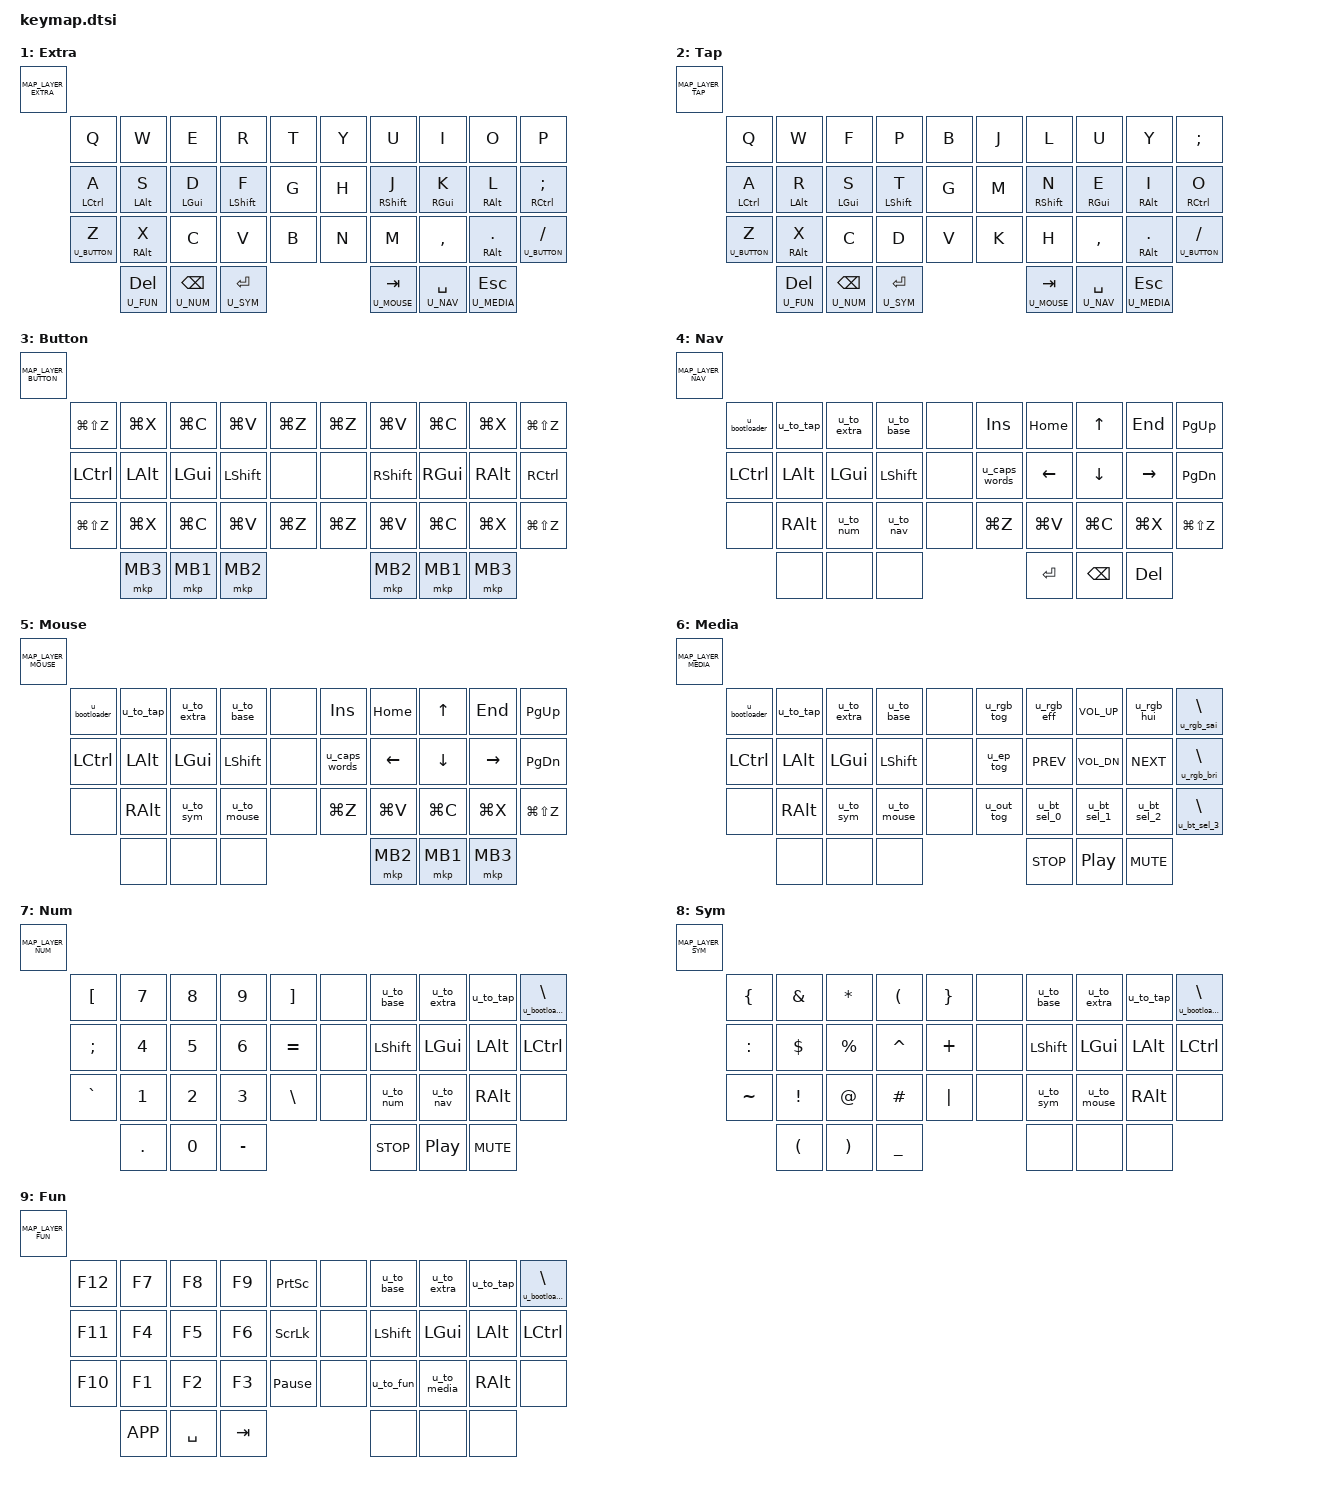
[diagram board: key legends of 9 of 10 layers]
#include <behaviors.dtsi>
#include <dt-bindings/zmk/bt.h>
#include <dt-bindings/zmk/keys.h>
#include <dt-bindings/zmk/mouse.h>
#include <dt-bindings/zmk/rgb.h>
#include <dt-bindings/zmk/ext_power.h>
#include <dt-bindings/zmk/outputs.h>

#include "default.h"

#define U_BASE   0
#define U_EXTRA  1
#define U_TAP    2
#define U_BUTTON 3
#define U_NAV    4
#define U_MOUSE  5
#define U_MEDIA  6
#define U_NUM    7
#define U_SYM    8
#define U_FUN    9

#define shift_mod_morph(NAME, BINDING, S_BINDING) \
  NAME: NAME {\
    compatible = "zmk,behavior-mod-morph";\
    bindings = <BINDING>, <S_BINDING>;\
    #binding-cells = <0>;\
    mods = <(MOD_LSFT|MOD_RSFT)>;\
  };

#define double_tap_guard(NAME, BINDING) \
  NAME: NAME {\
    compatible = "zmk,behavior-tap-dance";\
    #binding-cells = <0>;\
    tapping-term-ms = <200>;\
    bindings = <&none>, <BINDING>;\
  };

#define U_UND &kp LG(LS(Z))
#define U_CUT &kp LG(X)
#define U_CPY &kp LG(C)
#define U_PST &kp LG(V)
#define U_RDO &kp LG(Z)

#define U_BTN1 &mkp MB1
#define U_BTN2 &mkp MB2
#define U_BTN3 &mkp MB3


/ {
  behaviors {
    shift_mod_morph(sqt_under, &kp SQT, &kp UNDERSCORE)
    shift_mod_morph(minus_dqt, &kp MINUS, &kp DQT)
    shift_mod_morph(slash_lt, &kp SLASH, &kp LT)

    shift_mod_morph(u_caps_words, &caps_word, &kp CAPS)

    shift_mod_morph(u_rgb_tog, &rgb_ug RGB_TOG, &rgb_ug RGB_OFF)
    shift_mod_morph(u_rgb_eff, &rgb_ug RGB_EFF, &rgb_ug RGB_EFR)
    shift_mod_morph(u_rgb_hui, &rgb_ug RGB_HUI, &rgb_ug RGB_HUD)
    shift_mod_morph(u_rgb_sai, &rgb_ug RGB_SAI, &rgb_ug RGB_SAD)
    shift_mod_morph(u_rgb_bri, &rgb_ug RGB_BRI, &rgb_ug RGB_BRD)

    shift_mod_morph(u_ep_tog, &ext_power EP_TOG, &ext_power EP_OFF)

    shift_mod_morph(u_out_tog, &out OUT_TOG, &out OUT_USB)
    shift_mod_morph(u_bt_sel_0, &bt BT_SEL 0, &bt BT_SEL 0 &bt BT_CLR)
    shift_mod_morph(u_bt_sel_1, &bt BT_SEL 1, &bt BT_SEL 1 &bt BT_CLR)
    shift_mod_morph(u_bt_sel_2, &bt BT_SEL 2, &bt BT_SEL 2 &bt BT_CLR)
    shift_mod_morph(u_bt_sel_3, &bt BT_SEL 3, &bt BT_SEL 3 &bt BT_CLR)

    double_tap_guard(u_to_base, &to U_BASE)
    double_tap_guard(u_to_extra, &to U_EXTRA)
    double_tap_guard(u_to_tap, &to U_TAP)
    double_tap_guard(u_to_nav, &to U_NAV)
    double_tap_guard(u_to_mouse, &to U_MOUSE)
    double_tap_guard(u_to_media, &to U_MEDIA)
    double_tap_guard(u_to_num, &to U_NUM)
    double_tap_guard(u_to_sym, &to U_SYM)
    double_tap_guard(u_to_fun, &to U_FUN)
    double_tap_guard(u_bootloader, &bootloader)

    hm: hm {
      compatible = "zmk,behavior-hold-tap";
      #binding-cells = <2>;
      tapping-term-ms = <200>;
      quick-tap-ms = <0>;
      flavor = "tap-preferred";
      bindings = <&kp>, <&kp>;
    };

    u_lt: u_lt {
      compatible = "zmk,behavior-hold-tap";
      #binding-cells = <2>;
      tapping-term-ms = <200>;
      flavor = "tap-preferred";
      bindings = <&mo>, <&kp>;
    };
  };

  keymap {
    compatible = "zmk,keymap";

    Base {
      bindings = <MAP_LAYER_BASE( \
      // ╭─────────────┬─────────────┬─────────────┬─────────────┬─────────────╮   ╭─────────────┬─────────────┬─────────────┬─────────────┬─────────────╮
           &kp B,        &kp L,        &kp D,        &kp W,        &kp Z,            &sqt_under,   &kp F,        &kp O,        &kp U,        &kp J,      \
      // ├─────────────┼─────────────┼─────────────┼─────────────┼─────────────┤   ├─────────────┼─────────────┼─────────────┼─────────────┼─────────────┤
           &hm LCTRL N,  &hm LALT R,   &hm LGUI T,   &hm LSHIFT S, &kp G,            &kp Y,        &hm LSHIFT H, &hm LGUI A,   &hm LALT E,   &hm LCTRL I,\
      // ├─────────────┼─────────────┼─────────────┼─────────────┼─────────────┤   ├─────────────┼─────────────┼─────────────┼─────────────┼─────────────┤
           &u_lt U_BUTTON Q,&hm RALT X,&kp M,        &kp C,        &kp V,            &kp K,   &kp P,&kp DOT,&hm RALT &minus_dqt,&u_lt U_BUTTON &slash_lt,\
      // ╰─────────┬───┴─────────────┴─────────────┼─────────────┼─────────────┤   ├─────────────┼─────────────┼─────────────┴─────────────┴───┬─────────╯
                     &u_lt U_FUN DEL,    &u_lt U_NUM BSPC,   &u_lt U_SYM RET,        &u_lt U_MOUSE TAB,  &u_lt U_NAV SPACE,  &u_lt U_MEDIA ESC \
      //           ╰───────────────────┴───────────────────┴───────────────────╯   ╰───────────────────┴───────────────────┴───────────────────╯
      )>;
    };

    Extra {
      bindings = <MAP_LAYER_EXTRA( \
      // ╭─────────────┬─────────────┬─────────────┬─────────────┬─────────────╮   ╭─────────────┬─────────────┬─────────────┬─────────────┬─────────────╮
           &kp Q,        &kp W,        &kp E,        &kp R,        &kp T,            &kp Y,        &kp U,        &kp I,        &kp O,        &kp P,      \
      // ├─────────────┼─────────────┼─────────────┼─────────────┼─────────────┤   ├─────────────┼─────────────┼─────────────┼─────────────┼─────────────┤
           &hm LCTRL A,  &hm LALT S,   &hm LGUI D,   &hm LSHIFT F, &kp G,            &kp H,        &hm RSHIFT J, &hm RGUI K,   &hm RALT L,&hm RCTRL SEMI,\
      // ├─────────────┼─────────────┼─────────────┼─────────────┼─────────────┤   ├─────────────┼─────────────┼─────────────┼─────────────┼─────────────┤
           &u_lt U_BUTTON Z,&hm RALT X,&kp C,        &kp V,        &kp B,            &kp N,        &kp M,    &kp COMMA,&hm RALT DOT,&u_lt U_BUTTON SLASH,\
      // ╰─────────┬───┴─────────────┴─────────────┼─────────────┼─────────────┤   ├─────────────┼─────────────┼─────────────┴─────────────┴───┬─────────╯
                     &u_lt U_FUN DEL,    &u_lt U_NUM BSPC,   &u_lt U_SYM RET,        &u_lt U_MOUSE TAB,  &u_lt U_NAV SPACE,  &u_lt U_MEDIA ESC \
      //           ╰───────────────────┴───────────────────┴───────────────────╯   ╰───────────────────┴───────────────────┴───────────────────╯
      )>;
    };
    Tap {
      bindings = <MAP_LAYER_TAP( \
      // ╭─────────────┬─────────────┬─────────────┬─────────────┬─────────────╮   ╭─────────────┬─────────────┬─────────────┬─────────────┬─────────────╮
           &kp Q,        &kp W,        &kp F,        &kp P,        &kp B,            &kp J,        &kp L,        &kp U,        &kp Y,        &kp SEMI,   \
      // ├─────────────┼─────────────┼─────────────┼─────────────┼─────────────┤   ├─────────────┼─────────────┼─────────────┼─────────────┼─────────────┤
           &hm LCTRL A,  &hm LALT R,   &hm LGUI S,   &hm LSHIFT T, &kp G,            &kp M,        &hm RSHIFT N, &hm RGUI E,   &hm RALT I,   &hm RCTRL O,\
      // ├─────────────┼─────────────┼─────────────┼─────────────┼─────────────┤   ├─────────────┼─────────────┼─────────────┼─────────────┼─────────────┤
           &u_lt U_BUTTON Z,&hm RALT X,&kp C,        &kp D,        &kp V,            &kp K,        &kp H,    &kp COMMA,&hm RALT DOT,&u_lt U_BUTTON SLASH,\
      // ╰─────────┬───┴─────────────┴─────────────┼─────────────┼─────────────┤   ├─────────────┼─────────────┼─────────────┴─────────────┴───┬─────────╯
                     &u_lt U_FUN DEL,    &u_lt U_NUM BSPC,   &u_lt U_SYM RET,        &u_lt U_MOUSE TAB,  &u_lt U_NAV SPACE,  &u_lt U_MEDIA ESC \
      //           ╰───────────────────┴───────────────────┴───────────────────╯   ╰───────────────────┴───────────────────┴───────────────────╯
      )>;
    };
    Button {
      bindings = <MAP_LAYER_BUTTON( \
      // ╭─────────────┬─────────────┬─────────────┬─────────────┬─────────────╮   ╭─────────────┬─────────────┬─────────────┬─────────────┬─────────────╮
           U_UND,        U_CUT,        U_CPY,        U_PST,        U_RDO,            U_RDO,        U_PST,        U_CPY,        U_CUT,        U_UND,      \
      // ├─────────────┼─────────────┼─────────────┼─────────────┼─────────────┤   ├─────────────┼─────────────┼─────────────┼─────────────┼─────────────┤
           &kp LCTRL,    &kp LALT,     &kp LGUI,     &kp LSHIFT,   &none,            &none,        &kp RSHIFT,   &kp RGUI,     &kp RALT,     &kp RCTRL,  \
      // ├─────────────┼─────────────┼─────────────┼─────────────┼─────────────┤   ├─────────────┼─────────────┼─────────────┼─────────────┼─────────────┤
           U_UND,        U_CUT,        U_CPY,        U_PST,        U_RDO,            U_RDO,        U_PST,        U_CPY,        U_CUT,        U_UND,      \
      // ╰─────────┬───┴─────────────┴─────────────┼─────────────┼─────────────┤   ├─────────────┼─────────────┼─────────────┴─────────────┴───┬─────────╯
                     U_BTN3,             U_BTN1,             U_BTN2,                 U_BTN2,             U_BTN1,             U_BTN3            \
      //           ╰───────────────────┴───────────────────┴───────────────────╯   ╰───────────────────┴───────────────────┴───────────────────╯
      )>;
    };
    Nav {
      bindings = <MAP_LAYER_NAV( \
      // ╭─────────────┬─────────────┬─────────────┬─────────────┬─────────────╮   ╭─────────────┬─────────────┬─────────────┬─────────────┬─────────────╮
           &u_bootloader,&u_to_tap,    &u_to_extra,  &u_to_base,   &none,            &kp INS,      &kp HOME,     &kp UP,       &kp END,      &kp PG_UP,  \
      // ├─────────────┼─────────────┼─────────────┼─────────────┼─────────────┤   ├─────────────┼─────────────┼─────────────┼─────────────┼─────────────┤
           &kp LCTRL,    &kp LALT,     &kp LGUI,     &kp LSHIFT,   &none,            &u_caps_words,&kp LEFT,     &kp DOWN,     &kp RIGHT,    &kp PG_DN,  \
      // ├─────────────┼─────────────┼─────────────┼─────────────┼─────────────┤   ├─────────────┼─────────────┼─────────────┼─────────────┼─────────────┤
           &none,        &kp RALT,     &u_to_num,    &u_to_nav,    &none,            U_RDO,        U_PST,        U_CPY,        U_CUT,        U_UND,      \
      // ╰─────────┬───┴─────────────┴─────────────┼─────────────┼─────────────┤   ├─────────────┼─────────────┼─────────────┴─────────────┴───┬─────────╯
                     &none,              &none,              &none,                  &kp RET,            &kp BSPC,           &kp DEL           \
      //           ╰───────────────────┴───────────────────┴───────────────────╯   ╰───────────────────┴───────────────────┴───────────────────╯
      )>;
    };
    Mouse {
      bindings = <MAP_LAYER_MOUSE( \
      // ╭─────────────┬─────────────┬─────────────┬─────────────┬─────────────╮   ╭─────────────┬─────────────┬─────────────┬─────────────┬─────────────╮
           &u_bootloader,&u_to_tap,    &u_to_extra,  &u_to_base,   &none,            &kp INS,      &kp HOME,     &kp UP,       &kp END,      &kp PG_UP,  \
      // ├─────────────┼─────────────┼─────────────┼─────────────┼─────────────┤   ├─────────────┼─────────────┼─────────────┼─────────────┼─────────────┤
           &kp LCTRL,    &kp LALT,     &kp LGUI,     &kp LSHIFT,   &none,            &u_caps_words,&kp LEFT,     &kp DOWN,     &kp RIGHT,    &kp PG_DN,  \
      // ├─────────────┼─────────────┼─────────────┼─────────────┼─────────────┤   ├─────────────┼─────────────┼─────────────┼─────────────┼─────────────┤
           &none,        &kp RALT,     &u_to_sym,    &u_to_mouse,  &none,            U_RDO,        U_PST,        U_CPY,        U_CUT,        U_UND,      \
      // ╰─────────┬───┴─────────────┴─────────────┼─────────────┼─────────────┤   ├─────────────┼─────────────┼─────────────┴─────────────┴───┬─────────╯
                     &none,              &none,              &none,                  U_BTN2,             U_BTN1,             U_BTN3            \
      //           ╰───────────────────┴───────────────────┴───────────────────╯   ╰───────────────────┴───────────────────┴───────────────────╯
      )>;
    };
    Media {
      bindings = <MAP_LAYER_MEDIA( \
      // ╭─────────────┬─────────────┬─────────────┬─────────────┬─────────────╮   ╭─────────────┬─────────────┬─────────────┬─────────────┬─────────────╮
           &u_bootloader,&u_to_tap,    &u_to_extra,  &u_to_base,   &none,            &u_rgb_tog,   &u_rgb_eff,   &kp C_VOL_UP, &u_rgb_hui,   &u_rgb_sai, \
      // ├─────────────┼─────────────┼─────────────┼─────────────┼─────────────┤   ├─────────────┼─────────────┼─────────────┼─────────────┼─────────────┤
           &kp LCTRL,    &kp LALT,     &kp LGUI,     &kp LSHIFT,   &none,            &u_ep_tog,    &kp C_PREV,   &kp C_VOL_DN, &kp C_NEXT,   &u_rgb_bri, \
      // ├─────────────┼─────────────┼─────────────┼─────────────┼─────────────┤   ├─────────────┼─────────────┼─────────────┼─────────────┼─────────────┤
           &none,        &kp RALT,     &u_to_sym,    &u_to_mouse,  &none,            &u_out_tog,   &u_bt_sel_0,  &u_bt_sel_1,  &u_bt_sel_2,  &u_bt_sel_3,\
      // ╰─────────┬───┴─────────────┴─────────────┼─────────────┼─────────────┤   ├─────────────┼─────────────┼─────────────┴─────────────┴───┬─────────╯
                     &none,              &none,              &none,                  &kp C_STOP,         &kp C_PP,           &kp C_MUTE        \
      //           ╰───────────────────┴───────────────────┴───────────────────╯   ╰───────────────────┴───────────────────┴───────────────────╯
      )>;
    };
    Num {
      bindings = <MAP_LAYER_NUM( \
      // ╭─────────────┬─────────────┬─────────────┬─────────────┬─────────────╮   ╭─────────────┬─────────────┬─────────────┬─────────────┬─────────────╮
           &kp LBKT,     &kp N7,       &kp N8,       &kp N9,       &kp RBKT,         &none,        &u_to_base,   &u_to_extra,  &u_to_tap,  &u_bootloader,\
      // ├─────────────┼─────────────┼─────────────┼─────────────┼─────────────┤   ├─────────────┼─────────────┼─────────────┼─────────────┼─────────────┤
           &kp SEMI,     &kp N4,       &kp N5,       &kp N6,       &kp EQUAL,        &none,        &kp LSHFT,    &kp LGUI,     &kp LALT,     &kp LCTRL,  \
      // ├─────────────┼─────────────┼─────────────┼─────────────┼─────────────┤   ├─────────────┼─────────────┼─────────────┼─────────────┼─────────────┤
           &kp GRAVE,    &kp N1,       &kp N2,       &kp N3,       &kp BSLH,         &none,        &u_to_num,    &u_to_nav,    &kp RALT,     &none,      \
      // ╰─────────┬───┴─────────────┴─────────────┼─────────────┼─────────────┤   ├─────────────┼─────────────┼─────────────┴─────────────┴───┬─────────╯
                     &kp DOT,            &kp N0,             &kp MINUS,              &kp C_STOP,         &kp C_PP,           &kp C_MUTE        \
      //           ╰───────────────────┴───────────────────┴───────────────────╯   ╰───────────────────┴───────────────────┴───────────────────╯
      )>;
    };
    Sym {
      bindings = <MAP_LAYER_SYM( \
      // ╭─────────────┬─────────────┬─────────────┬─────────────┬─────────────╮   ╭─────────────┬─────────────┬─────────────┬─────────────┬─────────────╮
           &kp LBRC,     &kp AMPS,     &kp ASTRK,    &kp LPAR,     &kp RBRC,         &none,        &u_to_base,   &u_to_extra,  &u_to_tap,  &u_bootloader,\
      // ├─────────────┼─────────────┼─────────────┼─────────────┼─────────────┤   ├─────────────┼─────────────┼─────────────┼─────────────┼─────────────┤
           &kp COLON,    &kp DLLR,     &kp PRCNT,    &kp CARET,    &kp PLUS,         &none,        &kp LSHFT,    &kp LGUI,     &kp LALT,     &kp LCTRL,  \
      // ├─────────────┼─────────────┼─────────────┼─────────────┼─────────────┤   ├─────────────┼─────────────┼─────────────┼─────────────┼─────────────┤
           &kp TILDE,    &kp EXCL,     &kp AT,       &kp HASH,     &kp PIPE,         &none,        &u_to_sym,    &u_to_mouse,  &kp RALT,     &none,      \
      // ╰─────────┬───┴─────────────┴─────────────┼─────────────┼─────────────┤   ├─────────────┼─────────────┼─────────────┴─────────────┴───┬─────────╯
                     &kp LPAR,           &kp RPAR,           &kp UNDER,              &none,              &none,              &none             \
      //           ╰───────────────────┴───────────────────┴───────────────────╯   ╰───────────────────┴───────────────────┴───────────────────╯
      )>;
    };
    Fun {
      bindings = <MAP_LAYER_FUN( \
      // ╭─────────────┬─────────────┬─────────────┬─────────────┬─────────────╮   ╭─────────────┬─────────────┬─────────────┬─────────────┬─────────────╮
           &kp F12,      &kp F7,       &kp F8,       &kp F9,       &kp PSCRN,        &none,        &u_to_base,   &u_to_extra,  &u_to_tap,  &u_bootloader,\
      // ├─────────────┼─────────────┼─────────────┼─────────────┼─────────────┤   ├─────────────┼─────────────┼─────────────┼─────────────┼─────────────┤
           &kp F11,      &kp F4,       &kp F5,       &kp F6,       &kp SLCK,         &none,        &kp LSHFT,    &kp LGUI,     &kp LALT,     &kp LCTRL,  \
      // ├─────────────┼─────────────┼─────────────┼─────────────┼─────────────┤   ├─────────────┼─────────────┼─────────────┼─────────────┼─────────────┤
           &kp F10,      &kp F1,       &kp F2,       &kp F3,       &kp PAUSE_BREAK,  &none,        &u_to_fun,    &u_to_media,  &kp RALT,     &none,      \
      // ╰─────────┬───┴─────────────┴─────────────┼─────────────┼─────────────┤   ├─────────────┼─────────────┼─────────────┴─────────────┴───┬─────────╯
                     &kp K_APP,          &kp SPACE,          &kp TAB,                &none,              &none,              &none             \
      //           ╰───────────────────┴───────────────────┴───────────────────╯   ╰───────────────────┴───────────────────┴───────────────────╯
      )>;
    };
  };
};
